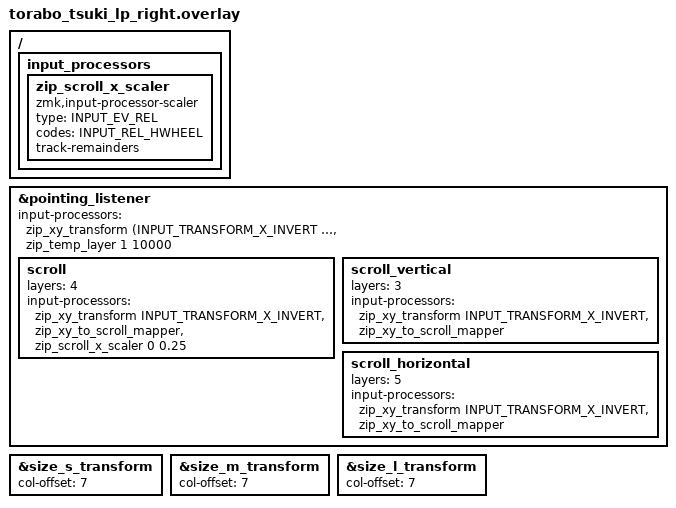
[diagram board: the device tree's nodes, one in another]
#include <zephyr/dt-bindings/input/input-event-codes.h>
#include "torabo_tsuki_lp.dtsi"
#include <input/processors.dtsi>
#include <dt-bindings/zmk/input_transform.h>

/ {
    input_processors {
        zip_scroll_x_scaler: zip_scroll_x_scaler {
            compatible = "zmk,input-processor-scaler";
            #input-processor-cells = <2>;
            type = <INPUT_EV_REL>;
            codes = <INPUT_REL_HWHEEL>;
            track-remainders;
        };
    };
};



&pointing_listener {
    input-processors = <
        &zip_xy_transform (INPUT_TRANSFORM_X_INVERT | INPUT_TRANSFORM_Y_INVERT)
        &zip_temp_layer 1 10000
    >;

       scroll {
        layers = <4>;
        input-processors = <
            &zip_xy_transform INPUT_TRANSFORM_X_INVERT
            &zip_xy_to_scroll_mapper
            &zip_scroll_x_scaler 0 0.25
        >;
    };

    scroll_vertical {
        layers = <3>;
        input-processors = <
            &zip_xy_transform INPUT_TRANSFORM_X_INVERT
            &zip_xy_to_scroll_mapper
        >;
    };

    scroll_horizontal {
        layers = <5>;
        input-processors = <
            &zip_xy_transform INPUT_TRANSFORM_X_INVERT
            &zip_xy_to_scroll_mapper
        >;
    };
};


&size_s_transform {
    col-offset = <7>;
};

&size_m_transform {
    col-offset = <7>;
};

&size_l_transform {
    col-offset = <7>;
};
